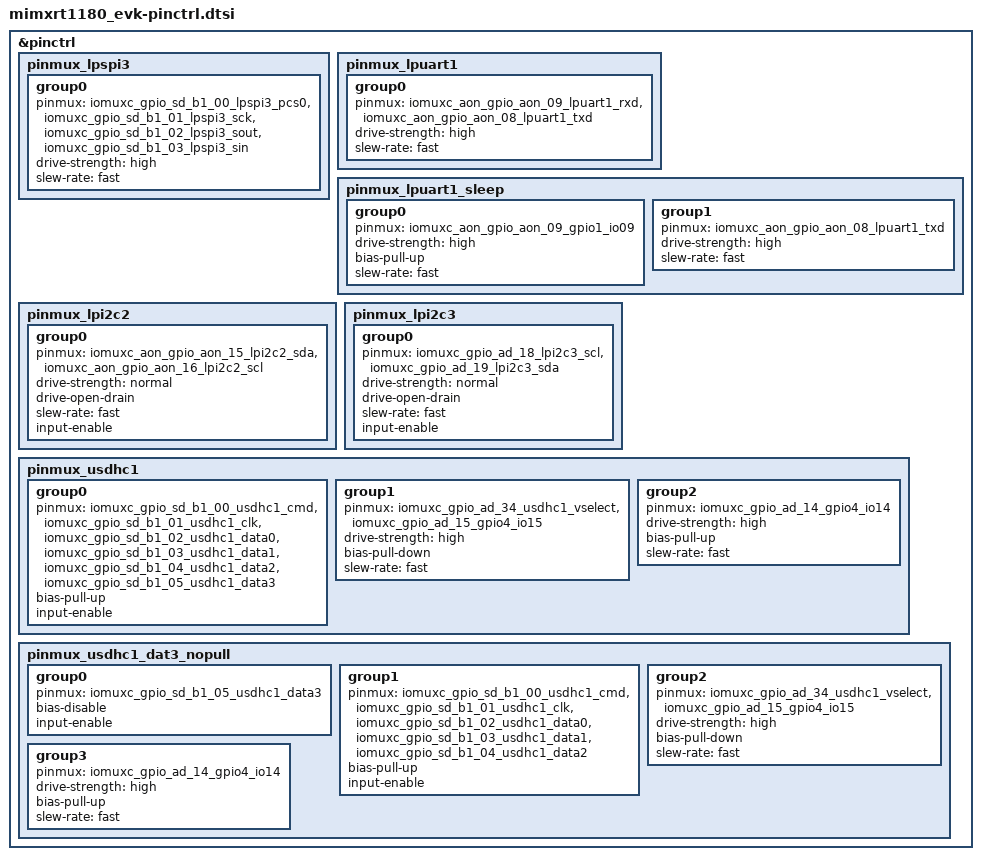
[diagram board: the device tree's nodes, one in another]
/*
 * Copyright 2024 NXP
 * SPDX-License-Identifier: Apache-2.0
 *
 */

#include <nxp/nxp_imx/rt/mimxrt1189cvm8b-pinctrl.dtsi>

&pinctrl {
	pinmux_lpspi3: pinmux_lpspi3 {
		group0 {
			pinmux = <&iomuxc_gpio_sd_b1_00_lpspi3_pcs0>,
				<&iomuxc_gpio_sd_b1_01_lpspi3_sck>,
				<&iomuxc_gpio_sd_b1_02_lpspi3_sout>,
				<&iomuxc_gpio_sd_b1_03_lpspi3_sin>;
			drive-strength = "high";
			slew-rate = "fast";
		};
	};

	pinmux_lpuart1: pinmux_lpuart1 {
		group0 {
			pinmux = <&iomuxc_aon_gpio_aon_09_lpuart1_rxd>,
				<&iomuxc_aon_gpio_aon_08_lpuart1_txd>;
			drive-strength = "high";
			slew-rate = "fast";
		};
	};

	pinmux_lpuart1_sleep: pinmux_lpuart1_sleep {
		group0 {
			pinmux = <&iomuxc_aon_gpio_aon_09_gpio1_io09>;
			drive-strength = "high";
			bias-pull-up;
			slew-rate = "fast";
		};
		group1 {
			pinmux = <&iomuxc_aon_gpio_aon_08_lpuart1_txd>;
			drive-strength = "high";
			slew-rate = "fast";
		};
	};

	/* Connected to FXLS8974 */
	pinmux_lpi2c2: pinmux_lpi2c2 {
		group0 {
			pinmux = <&iomuxc_aon_gpio_aon_15_lpi2c2_sda>,
				<&iomuxc_aon_gpio_aon_16_lpi2c2_scl>;
			drive-strength = "normal";
			drive-open-drain;
			slew-rate = "fast";
			input-enable;
		};
	};

	pinmux_lpi2c3: pinmux_lpi2c3 {
		group0 {
			pinmux = <&iomuxc_gpio_ad_18_lpi2c3_scl>,
				<&iomuxc_gpio_ad_19_lpi2c3_sda>;
			drive-strength = "normal";
			drive-open-drain;
			slew-rate = "fast";
			input-enable;
		};
	};

	pinmux_usdhc1: pinmux_usdhc1 {
		group0 {
			pinmux = <&iomuxc_gpio_sd_b1_00_usdhc1_cmd>,
				<&iomuxc_gpio_sd_b1_01_usdhc1_clk>,
				<&iomuxc_gpio_sd_b1_02_usdhc1_data0>,
				<&iomuxc_gpio_sd_b1_03_usdhc1_data1>,
				<&iomuxc_gpio_sd_b1_04_usdhc1_data2>,
				<&iomuxc_gpio_sd_b1_05_usdhc1_data3>;
			bias-pull-up;
			input-enable;
		};
		group1 {
			pinmux = <&iomuxc_gpio_ad_34_usdhc1_vselect>,
				<&iomuxc_gpio_ad_15_gpio4_io15>;
			drive-strength = "high";
			bias-pull-down;
			slew-rate = "fast";
		};
		group2 {
			pinmux = <&iomuxc_gpio_ad_14_gpio4_io14>;
			drive-strength = "high";
			bias-pull-up;
			slew-rate = "fast";
		};
	};

	/* removes pull on dat3 for card detect */
	pinmux_usdhc1_dat3_nopull: pinmux_usdhc1_dat3_nopull {
		group0 {
			pinmux = <&iomuxc_gpio_sd_b1_05_usdhc1_data3>;
			bias-disable;
			input-enable;
		};
		group1 {
			pinmux = <&iomuxc_gpio_sd_b1_00_usdhc1_cmd>,
				<&iomuxc_gpio_sd_b1_01_usdhc1_clk>,
				<&iomuxc_gpio_sd_b1_02_usdhc1_data0>,
				<&iomuxc_gpio_sd_b1_03_usdhc1_data1>,
				<&iomuxc_gpio_sd_b1_04_usdhc1_data2>;
			bias-pull-up;
			input-enable;
		};
		group2 {
			pinmux = <&iomuxc_gpio_ad_34_usdhc1_vselect>,
				<&iomuxc_gpio_ad_15_gpio4_io15>;
			drive-strength = "high";
			bias-pull-down;
			slew-rate = "fast";
		};
		group3 {
			pinmux = <&iomuxc_gpio_ad_14_gpio4_io14>;
			drive-strength = "high";
			bias-pull-up;
			slew-rate = "fast";
		};
	};
};
